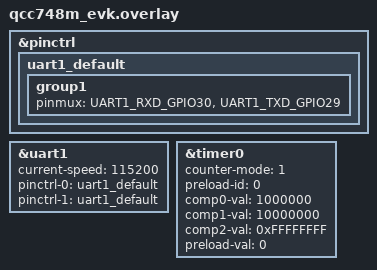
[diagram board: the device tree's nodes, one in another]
/*
 * Copyright (c) 2026 Qualcomm Technologies, Inc. and/or its subsidiaries
 *
 * SPDX-License-Identifier: Apache-2.0
 *
 * qcc748m_evk board overlay for zephyr/tests/drivers/uart/uart_mix_fifo_poll.
 * Provides the `dut:` alias (uart1, GPIO29/30) and `counter_dev:` alias
 * (timer0) required by the test. hw-flow-control is intentionally omitted
 * (see dut node comment below). Only GPIO29(TX)<->GPIO30(RX) loopback needed.
 *
 * Test requires a physical loopback wire on uart1 (TX<->RX per the
 * source comment "RX and TX pins have to be connected together").
 * Without the wire, expect a build pass but a runtime failure/hang.
 *
 * The base scenario has a Nordic-only platform_allow allowlist, so
 * `west twister` static-filters qcc748m_evk out. Inject via west build
 * (which ignores platform_allow):
 *   west build -p always -b qcc748m_evk/qcc748 -d C:/b17 \
 *     zephyr/tests/drivers/uart/uart_mix_fifo_poll \
 *     -- -DDTC_OVERLAY_FILE=<abs>/board_overlays/uart_mix_fifo_poll/qcc748m_evk.overlay
 */

&pinctrl {
	uart1_default: uart1_default {
		group1 {
			pinmux = <UART1_RXD_GPIO30>,
				<UART1_TXD_GPIO29>;
		};
	};
};

/*
 * The driver binding requires both "default" and "sleep" pinctrl states.
 * Point "sleep" at the same default pin group since this test never enters
 * the sleep state.
 *
 * hw-flow-control is intentionally omitted: with a single-board RTS<->CTS
 * loopback wire the counter's 1ms RX-IRQ toggle causes RX FIFO to fill,
 * hardware deasserts RTS, CTS blocks TX, and qc7xx_uart_putchar() spins
 * up to 100ms (deadlock). No loopback on GPIO27/28 is needed.
 */
dut: &uart1 {
	status = "okay";
	current-speed = <115200>;
	pinctrl-0 = <&uart1_default>;
	pinctrl-1 = <&uart1_default>;
	pinctrl-names = "default", "sleep";
};

counter_dev: &timer0 {
	status = "okay";
	counter-mode = <1>;
	preload-id = <0>;
	comp0-val = <1000000>;
	comp1-val = <10000000>;
	comp2-val = <0xFFFFFFFF>;
	preload-val = <0>;
};
